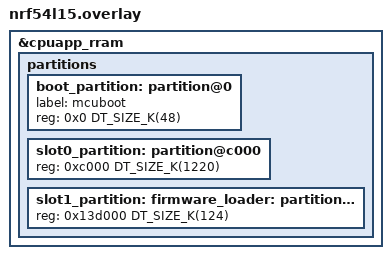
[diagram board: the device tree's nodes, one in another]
/*
 * Copyright (c) 2025 Nordic Semiconductor ASA
 *
 * SPDX-License-Identifier: LicenseRef-Nordic-5-Clause
 */

/delete-node/ &boot_partition;
/delete-node/ &slot0_partition;
/delete-node/ &slot1_partition;

&cpuapp_rram {
	partitions {
		boot_partition: partition@0 {
			label = "mcuboot";
			reg = <0x0 DT_SIZE_K(48)>;
		};

		slot0_partition: partition@c000 {
			reg = <0xc000 DT_SIZE_K(1220)>;
		};

		slot1_partition: firmware_loader: partition@13d000 {
			reg = <0x13d000 DT_SIZE_K(124)>;
		};
	};
};
